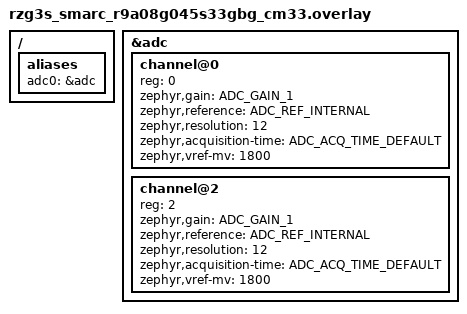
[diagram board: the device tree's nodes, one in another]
/*
 * Copyright (c) 2024 Renesas Electronics Corporation
 *
 * SPDX-License-Identifier: Apache-2.0
 */


/ {
	aliases {
		adc0 = &adc;
	};
};

&adc {
	status = "okay";
	#address-cells = <1>;
	#size-cells = <0>;

	channel@0 {
		reg = <0>;
		zephyr,gain = "ADC_GAIN_1";
		zephyr,reference = "ADC_REF_INTERNAL";
		zephyr,resolution = <12>;
		zephyr,acquisition-time = <ADC_ACQ_TIME_DEFAULT>;
		zephyr,vref-mv = <1800>;
	};

	channel@2 {
		reg = <2>;
		zephyr,gain = "ADC_GAIN_1";
		zephyr,reference = "ADC_REF_INTERNAL";
		zephyr,resolution = <12>;
		zephyr,acquisition-time = <ADC_ACQ_TIME_DEFAULT>;
		zephyr,vref-mv = <1800>;
	};
};
